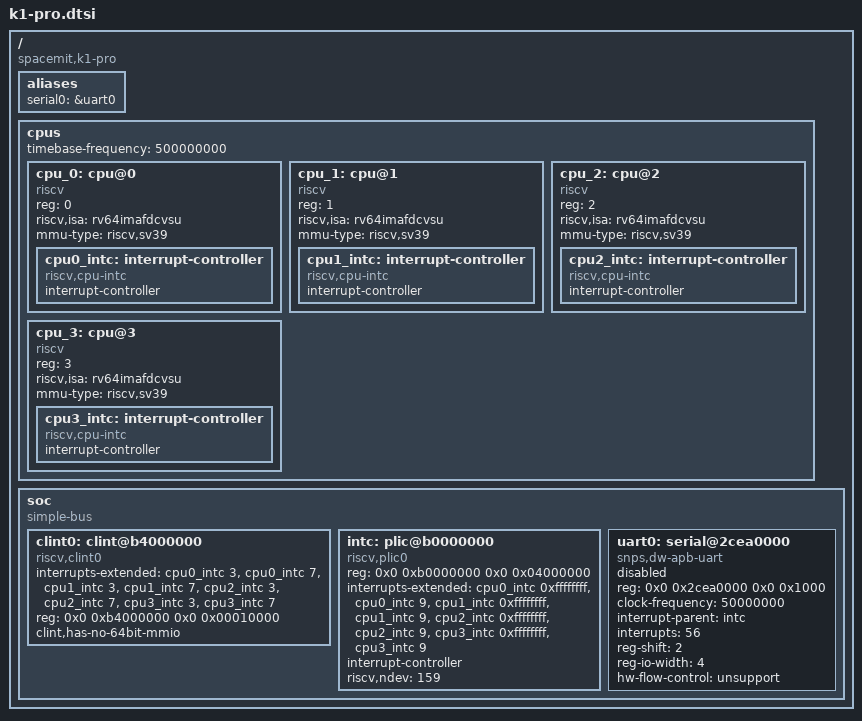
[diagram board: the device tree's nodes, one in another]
// SPDX-License-Identifier: (GPL-2.0 OR MIT)
/* Copyright (c) 2022 Spacemit, Inc */

/dts-v1/;

/dts-v1/;
/ {
	compatible = "spacemit,k1-pro", "riscv";
	#address-cells = <2>;
	#size-cells = <2>;

	aliases {
		serial0 = &uart0;
	};

	cpus {
		#address-cells = <1>;
		#size-cells = <0>;
		timebase-frequency = <500000000>;
		cpu_0: cpu@0 {
			device_type = "cpu";
			reg = <0>;
			status = "okay";
			compatible = "riscv";
			riscv,isa = "rv64imafdcvsu";
			mmu-type = "riscv,sv39";

			cpu0_intc: interrupt-controller {
				#interrupt-cells = <1>;
				compatible = "riscv,cpu-intc";
				interrupt-controller;
			};
		};
		cpu_1: cpu@1 {
			device_type = "cpu";
			reg = <1>;
			status = "okay";
			compatible = "riscv";
			riscv,isa = "rv64imafdcvsu";
			mmu-type = "riscv,sv39";

			cpu1_intc: interrupt-controller {
				#interrupt-cells = <1>;
				compatible = "riscv,cpu-intc";
				interrupt-controller;
			};
		};
		cpu_2: cpu@2 {
			device_type = "cpu";
			reg = <2>;
			status = "okay";
			compatible = "riscv";
			riscv,isa = "rv64imafdcvsu";
			mmu-type = "riscv,sv39";

			cpu2_intc: interrupt-controller {
				#interrupt-cells = <1>;
				compatible = "riscv,cpu-intc";
				interrupt-controller;
			};
		};
		cpu_3: cpu@3 {
			device_type = "cpu";
			reg = <3>;
			status = "okay";
			compatible = "riscv";
			riscv,isa = "rv64imafdcvsu";
			mmu-type = "riscv,sv39";

			cpu3_intc: interrupt-controller {
				#interrupt-cells = <1>;
				compatible = "riscv,cpu-intc";
				interrupt-controller;
			};
		};
	};

	soc {
		compatible = "simple-bus";
		#address-cells = <2>;
		#size-cells = <2>;
		ranges;

		clint0: clint@b4000000 {
			compatible = "riscv,clint0";
			interrupts-extended = <
				&cpu0_intc  3 &cpu0_intc  7
				&cpu1_intc  3 &cpu1_intc  7
				&cpu2_intc  3 &cpu2_intc  7
				&cpu3_intc  3 &cpu3_intc  7
			>;
			reg = <0x0 0xb4000000 0x0 0x00010000>;
			clint,has-no-64bit-mmio;
		};

		intc: plic@b0000000 {
			compatible = "riscv,plic0";
			reg = <0x0 0xb0000000 0x0 0x04000000>;

			interrupts-extended = <
				&cpu0_intc 0xffffffff &cpu0_intc 9
				&cpu1_intc 0xffffffff &cpu1_intc 9
				&cpu2_intc 0xffffffff &cpu2_intc 9
				&cpu3_intc 0xffffffff &cpu3_intc 9
			>;

			interrupt-controller;
			#interrupt-cells = <1>;
			#address-cells = <0x0>;
			riscv,ndev = <159>;
		};

		uart0: serial@2cea0000 {
			compatible = "snps,dw-apb-uart";
			reg = <0x0 0x2cea0000 0x0 0x1000>;
			clock-frequency = <50000000>;
			interrupt-parent = <&intc>;
			interrupts = <56>;
			reg-shift = <2>;
			reg-io-width = <4>;
			hw-flow-control = "unsupport";
			status = "disabled";
		};
	};
};

